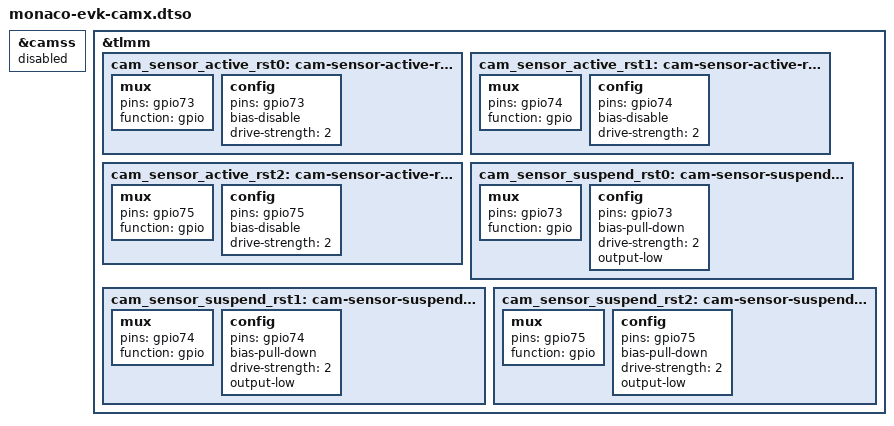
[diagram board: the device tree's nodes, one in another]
// SPDX-License-Identifier: BSD-3-Clause
/*
 * Copyright (c) Qualcomm Technologies, Inc. and/or its subsidiaries.
 */

/dts-v1/;
/plugin/;

#include <dt-bindings/clock/qcom,qcs8300-gcc.h>
#include <dt-bindings/clock/qcom,sa8775p-camcc.h>
#include <dt-bindings/interconnect/qcom,qcs8300-rpmh.h>
#include <dt-bindings/interrupt-controller/arm-gic.h>
#include <dt-bindings/power/qcom-rpmpd.h>

#include "monaco-camera.dtsi"
#include "monaco-evk-camera-sensor.dtsi"

&camss {
	status = "disabled";
};

&tlmm {
	cam_sensor_active_rst0: cam-sensor-active-rst0 {
		/* RESET */
		mux {
			pins = "gpio73";
			function = "gpio";
		};

		config {
			pins = "gpio73";
			bias-disable; /* No PULL */
			drive-strength = <2>; /* 2 MA */
		};
	};

	cam_sensor_active_rst1: cam-sensor-active-rst1 {
		/* RESET */
		mux {
			pins = "gpio74";
			function = "gpio";
		};

		config {
			pins = "gpio74";
			bias-disable; /* No PULL */
			drive-strength = <2>; /* 2 MA */
		};
	};

	cam_sensor_active_rst2: cam-sensor-active-rst2 {
		/* RESET */
		mux {
			pins = "gpio75";
			function = "gpio";
		};

		config {
			pins = "gpio75";
			bias-disable; /* No PULL */
			drive-strength = <2>; /* 2 MA */
		};
	};

	cam_sensor_suspend_rst0: cam-sensor-suspend-rst0 {
		/* RESET */
		mux {
			pins = "gpio73";
			function = "gpio";
		};

		config {
			pins = "gpio73";
			bias-pull-down; /* PULL DOWN */
			drive-strength = <2>; /* 2 MA */
			output-low;
		};
	};

	cam_sensor_suspend_rst1: cam-sensor-suspend-rst1 {
		/* RESET */
		mux {
			pins = "gpio74";
			function = "gpio";
		};
		config {
			pins = "gpio74";
			bias-pull-down; /* PULL DOWN */
			drive-strength = <2>; /* 2 MA */
			output-low;
		};
	};

	cam_sensor_suspend_rst2: cam-sensor-suspend-rst2 {
		/* RESET */
		mux {
			pins = "gpio75";
			function = "gpio";
		};
		config {
			pins = "gpio75";
			bias-pull-down; /* PULL DOWN */
			drive-strength = <2>; /* 2 MA */
			output-low;
		};
	};
};
